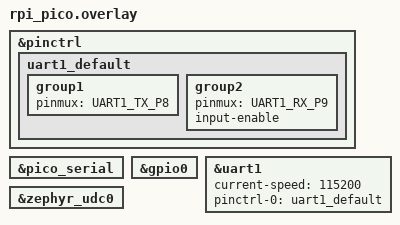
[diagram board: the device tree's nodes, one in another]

#include <zephyr/dt-bindings/pinctrl/rpi-pico-rp2040-pinctrl.h>
#include <raspberrypi/rpi_pico/rp2040.dtsi>

&pinctrl {
    /* configuration for the usart0 "default" state */
    uart1_default: uart1_default {
        group1 {
            pinmux = <UART1_TX_P8>;
            };
        group2 {
            pinmux = <UART1_RX_P9>;
            /* enable input on pin 1 */
            input-enable;
        };
    };
};

&pico_serial {
    status = "okay";
};

&gpio0 {
    status = "okay";
};

&uart1{
    current-speed = <115200>;
    status = "okay";
    pinctrl-0 = <&uart1_default>;
    pinctrl-names = "default";
};


&zephyr_udc0 {
	status = "okay";
};
